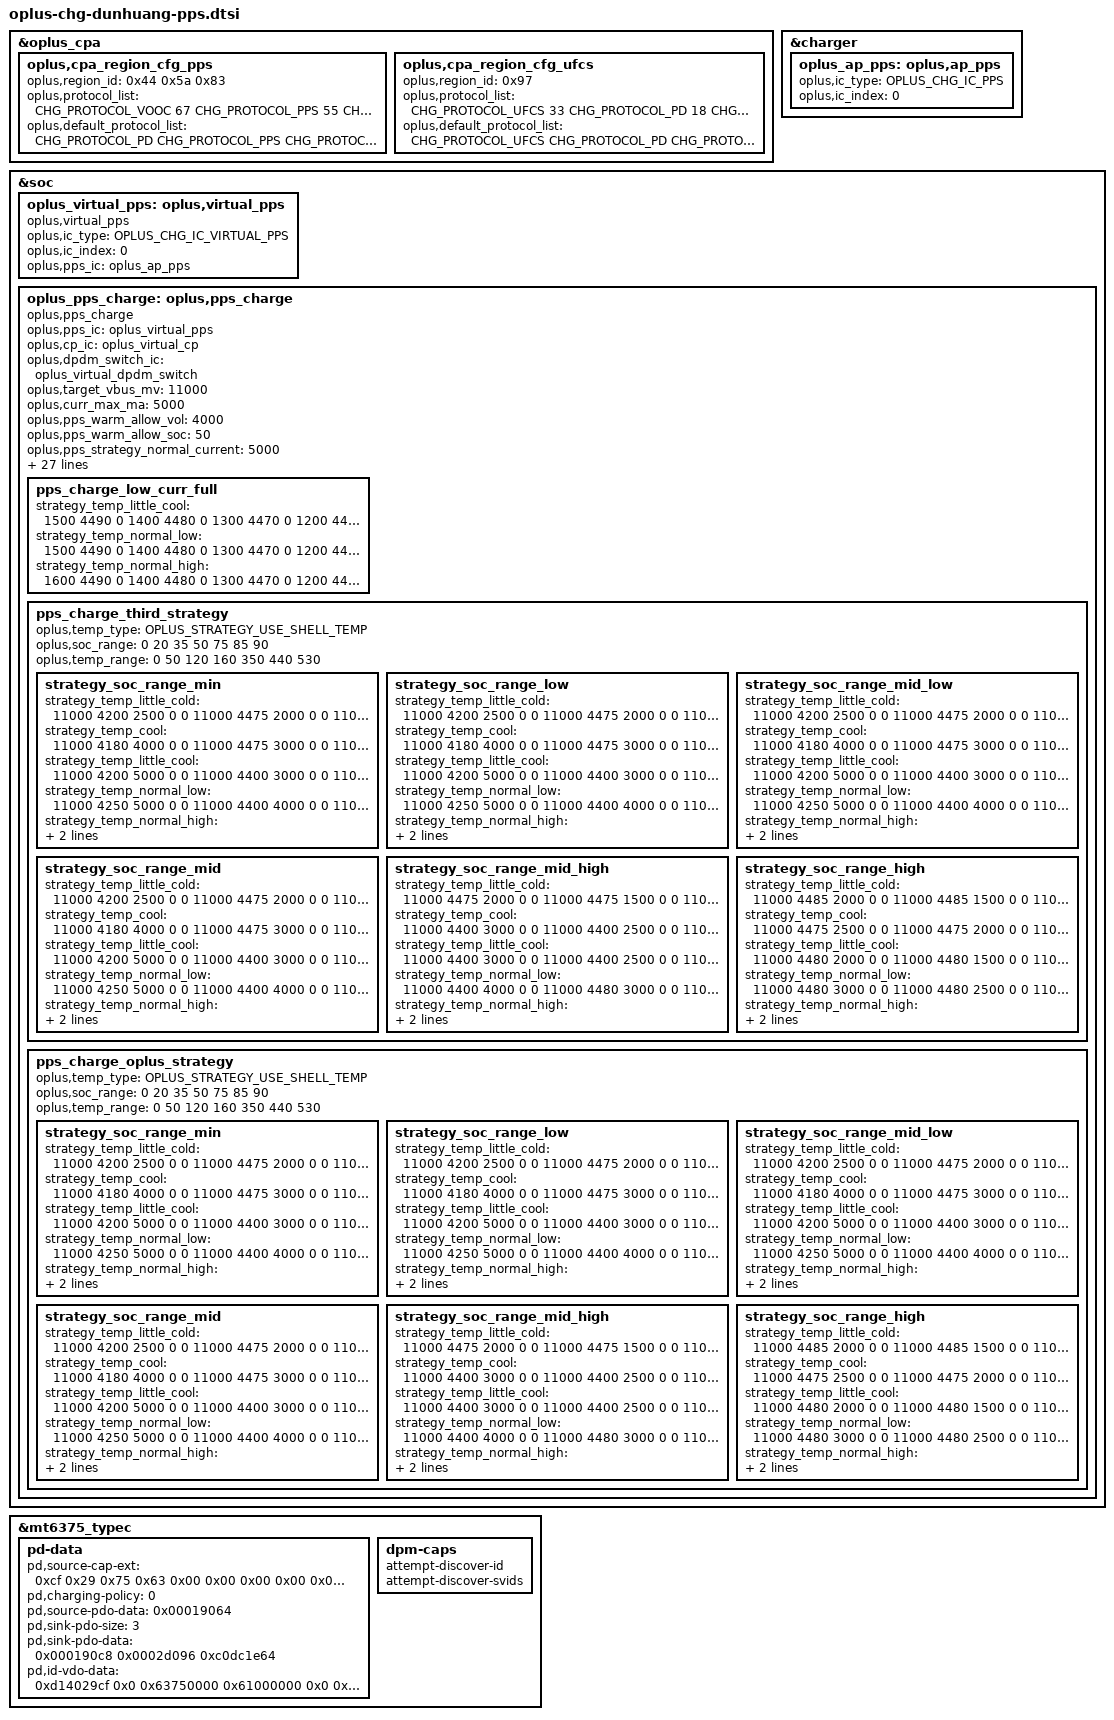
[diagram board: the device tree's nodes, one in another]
//ifdef OPLUS_FEATURE_CHG_BASIC
&oplus_cpa {
	oplus,cpa_region_cfg_pps {
		oplus,region_id = /bits/ 8 <0x44 0x5a 0x83>; /* europe: 0x44, Republic of Serbia:0x5a, Saudi Arabia: 0x83 */
		oplus,protocol_list = <CHG_PROTOCOL_VOOC 67
					CHG_PROTOCOL_PPS  55
					CHG_PROTOCOL_PD   18
					CHG_PROTOCOL_QC   18>;
		oplus,default_protocol_list = <CHG_PROTOCOL_PD
					CHG_PROTOCOL_PPS
					CHG_PROTOCOL_VOOC>;
	};
	oplus,cpa_region_cfg_ufcs {
		oplus,region_id = /bits/ 8 <0x97>; /*China:0x97*/
		oplus,protocol_list = <CHG_PROTOCOL_UFCS 33
				       CHG_PROTOCOL_PD 18
				       CHG_PROTOCOL_VOOC 67
				       CHG_PROTOCOL_QC 18>;
		oplus,default_protocol_list = <CHG_PROTOCOL_UFCS
					       CHG_PROTOCOL_PD
					       CHG_PROTOCOL_VOOC>;
	};
};

&charger {
	oplus_ap_pps: oplus,ap_pps {
		oplus,ic_type = <OPLUS_CHG_IC_PPS>;
		oplus,ic_index = <0>;
	};
};

&soc {
	oplus_virtual_pps: oplus,virtual_pps {
		compatible = "oplus,virtual_pps";

		oplus,ic_type = <OPLUS_CHG_IC_VIRTUAL_PPS>;
		oplus,ic_index = <0>;
		oplus,pps_ic = <&oplus_ap_pps>;
	};
	oplus_pps_charge: oplus,pps_charge {
		compatible = "oplus,pps_charge";
		oplus,pps_ic = <&oplus_virtual_pps>;
		oplus,cp_ic = <&oplus_virtual_cp>;
		oplus,dpdm_switch_ic = <&oplus_virtual_dpdm_switch>;

		// oplus,impedance_unit = <&oplus_pps_impedance_unit>;

		oplus,target_vbus_mv = <11000>;
		oplus,curr_max_ma = <5000>;

		oplus,pps_warm_allow_vol = <4000>;
		oplus,pps_warm_allow_soc = <50>;
		oplus,pps_strategy_normal_current = <5000>;
		oplus,pps_over_high_or_low_current = <5000>;
		oplus,pps_timeout_third = <10800>;
		oplus,pps_timeout_oplus = <10800>;
		oplus,pps_ibat_over_third = <12000>;
		oplus,pps_ibat_over_oplus = <12000>;
		oplus,pps_full_cool_sw_vbat = <4485>;
		oplus,pps_full_normal_sw_vbat = <4490>;
		oplus,pps_full_normal_hw_vbat = <4500>;
		oplus,pps_full_ffc_vbat = <4520>;
		oplus,pps_full_warm_vbat = <4130>;
		oplus,pps_full_cool_sw_vbat_third = <4485>;
		oplus,pps_full_normal_sw_vbat_third= <4490>;
		oplus,pps_full_normal_hw_vbat_third = <4500>;
		oplus,pps_current_change_timeout = <100>;
		oplus,pps_r_default = <270 45 10 45 20 20 20>;
		oplus,pps_rmos_mohm = <5>;
		oplus,pps_r_limit = <150 100 80 70 30>;
		oplus,pps_strategy_batt_high_temp = <410 420 430 400 410 420>;
		oplus,pps_strategy_high_current = <3000 2000 2000 3000 3000 3000>;
		oplus,pps_charge_strategy_soc = <0 20 35 50 75 85 90>;
		oplus,pps_charge_strategy_temp = <0 50 120 160 350 440 530>;
		oplus,pps_low_curr_full_strategy_temp = <0 200 350 440>;

		pps_charge_low_curr_full {
			strategy_temp_little_cool = 	<1500 4490 0
							 1400 4480 0
							 1300 4470 0
							 1200 4460 0
							 1100 4450 1>;
			strategy_temp_normal_low =	<1500 4490 0
                                                         1400 4480 0
                                                         1300 4470 0
                                                         1200 4460 0
                                                         1100 4450 1>;
			strategy_temp_normal_high = 	<1600 4490 0
                                                         1400 4480 0
                                                         1300 4470 0
                                                         1200 4460 0
                                                         1100 4450 1>;
		};

		pps_charge_third_strategy {
			oplus,temp_type = <OPLUS_STRATEGY_USE_SHELL_TEMP>;
			oplus,soc_range = <0 20 35 50 75 85 90>;
			oplus,temp_range = <0 50 120 160 350 440 530>;

			strategy_soc_range_min {
				strategy_temp_little_cold =	<11000 4200 2500 0 0
								11000 4475 2000 0 0
								11000 4475 1500 0 0
								11000 4485 1000 1 0>;
				strategy_temp_cool =		<11000 4180 4000 0 0
								11000 4475 3000 0 0
								11000 4475 2500 0 0
								11000 4475 2000 0 0
								11000 4475 1500 0 0
								11000 4485 1000 1 0>;
				strategy_temp_little_cool =	<11000 4200 5000 0 0
								11000 4400 3000 0 0
								11000 4400 2500 0 0
								11000 4480 2000 0 0
								11000 4480 1500 0 0
								11000 4490 1000 1 0>;
				strategy_temp_normal_low =	<11000 4250 5000 0 0
								11000 4400 4000 0 0
								11000 4480 3000 0 0
								11000 4480 2500 0 0
								11000 4480 2000 0 0
								11000 4480 1500 0 0
								11000 4490 1000 1 0>;
				strategy_temp_normal_high =	<11000 4250 5000 0 0
								11000 4400 4000 0 0
								11000 4480 3000 0 0
								11000 4480 2500 0 0
								11000 4480 2000 0 0
								11000 4480 1500 0 0
								11000 4490 1000 1 0>;
				strategy_temp_warm =		<11000 4130 1000 1 0>;
			};
			strategy_soc_range_low {
				strategy_temp_little_cold =	<11000 4200 2500 0 0
								11000 4475 2000 0 0
								11000 4475 1500 0 0
								11000 4485 1000 1 0>;
				strategy_temp_cool =		<11000 4180 4000 0 0
								11000 4475 3000 0 0
								11000 4475 2500 0 0
								11000 4475 2000 0 0
								11000 4475 1500 0 0
								11000 4485 1000 1 0>;
				strategy_temp_little_cool =	<11000 4200 5000 0 0
								11000 4400 3000 0 0
								11000 4400 2500 0 0
								11000 4480 2000 0 0
								11000 4480 1500 0 0
								11000 4490 1000 1 0>;
				strategy_temp_normal_low =	<11000 4250 5000 0 0
								11000 4400 4000 0 0
								11000 4480 3000 0 0
								11000 4480 2500 0 0
								11000 4480 2000 0 0
								11000 4480 1500 0 0
								11000 4490 1000 1 0>;
				strategy_temp_normal_high =	<11000 4250 5000 0 0
								11000 4400 4000 0 0
								11000 4480 3000 0 0
								11000 4480 2500 0 0
								11000 4480 2000 0 0
								11000 4480 1500 0 0
								11000 4490 1000 1 0>;
				strategy_temp_warm =		<11000 4130 1000 1 0>;
			};
			strategy_soc_range_mid_low {
				strategy_temp_little_cold =	<11000 4200 2500 0 0
								11000 4475 2000 0 0
								11000 4475 1500 0 0
								11000 4485 1000 1 0>;
				strategy_temp_cool =		<11000 4180 4000 0 0
								11000 4475 3000 0 0
								11000 4475 2500 0 0
								11000 4475 2000 0 0
								11000 4475 1500 0 0
								11000 4485 1000 1 0>;
				strategy_temp_little_cool =	<11000 4200 5000 0 0
								11000 4400 3000 0 0
								11000 4400 2500 0 0
								11000 4480 2000 0 0
								11000 4480 1500 0 0
								11000 4490 1000 1 0>;
				strategy_temp_normal_low =	<11000 4250 5000 0 0
								11000 4400 4000 0 0
								11000 4480 3000 0 0
								11000 4480 2500 0 0
								11000 4480 2000 0 0
								11000 4480 1500 0 0
								11000 4490 1000 1 0>;
				strategy_temp_normal_high =	<11000 4250 5000 0 0
								11000 4400 4000 0 0
								11000 4480 3000 0 0
								11000 4480 2500 0 0
								11000 4480 2000 0 0
								11000 4480 1500 0 0
								11000 4490 1000 1 0>;
				strategy_temp_warm =		<11000 4130 1000 1 0>;
			};
			strategy_soc_range_mid {
				strategy_temp_little_cold =	<11000 4200 2500 0 0
								11000 4475 2000 0 0
								11000 4475 1500 0 0
								11000 4485 1000 1 0>;
				strategy_temp_cool =		<11000 4180 4000 0 0
								11000 4475 3000 0 0
								11000 4475 2500 0 0
								11000 4475 2000 0 0
								11000 4475 1500 0 0
								11000 4485 1000 1 0>;
				strategy_temp_little_cool =	<11000 4200 5000 0 0
								11000 4400 3000 0 0
								11000 4400 2500 0 0
								11000 4480 2000 0 0
								11000 4480 1500 0 0
								11000 4490 1000 1 0>;
				strategy_temp_normal_low =	<11000 4250 5000 0 0
								11000 4400 4000 0 0
								11000 4480 3000 0 0
								11000 4480 2500 0 0
								11000 4480 2000 0 0
								11000 4480 1500 0 0
								11000 4490 1000 1 0>;
				strategy_temp_normal_high =	<11000 4250 5000 0 0
								11000 4400 4000 0 0
								11000 4480 3000 0 0
								11000 4480 2500 0 0
								11000 4480 2000 0 0
								11000 4480 1500 0 0
								11000 4490 1000 1 0>;
				strategy_temp_warm =		<11000 4130 1000 1 0>;
			};
			strategy_soc_range_mid_high {
				strategy_temp_little_cold =	<11000 4475 2000 0 0
								11000 4475 1500 0 0
								11000 4485 1000 1 0>;
				strategy_temp_cool =		<11000 4400 3000 0 0
								11000 4400 2500 0 0
								11000 4475 2000 0 0
								11000 4475 1500 0 0
								11000 4485 1000 1 0>;
				strategy_temp_little_cool =	<11000 4400 3000 0 0
								11000 4400 2500 0 0
								11000 4480 2000 0 0
								11000 4480 1500 0 0
								11000 4490 1000 1 0>;
				strategy_temp_normal_low =	<11000 4400 4000 0 0
								11000 4480 3000 0 0
								11000 4480 2500 0 0
								11000 4480 2000 0 0
								11000 4480 1500 0 0
								11000 4490 1000 1 0>;
				strategy_temp_normal_high =	<11000 4400 4000 0 0
								11000 4480 3000 0 0
								11000 4480 2500 0 0
								11000 4480 2000 0 0
								11000 4480 1500 0 0
								11000 4490 1000 1 0>;
				strategy_temp_warm =		<11000 4130 1000 1 0>;
			};
			strategy_soc_range_high {
				strategy_temp_little_cold =	<11000 4485 2000 0 0
								11000 4485 1500 0 0
								11000 4485 1000 1 0>;
				strategy_temp_cool =		<11000 4475 2500 0 0
								11000 4475 2000 0 0
								11000 4475 1500 0 0
								11000 4485 1000 1 0>;
				strategy_temp_little_cool =	<11000 4480 2000 0 0
								11000 4480 1500 0 0
								11000 4490 1000 1 0>;
				strategy_temp_normal_low =	<11000 4480 3000 0 0
								11000 4480 2500 0 0
								11000 4480 2000 0 0
								11000 4480 1500 0 0
								11000 4490 1000 1 0>;
				strategy_temp_normal_high =	<11000 4480 3000 0 0
								11000 4480 2500 0 0
								11000 4480 2000 0 0
								11000 4480 1500 0 0
								11000 4490 1000 1 0>;
				strategy_temp_warm =		<11000 4130 1000 1 0>;
			};
		};

		pps_charge_oplus_strategy {
			oplus,temp_type = <OPLUS_STRATEGY_USE_SHELL_TEMP>;
			oplus,soc_range = <0 20 35 50 75 85 90>;
			oplus,temp_range = <0 50 120 160 350 440 530>;

			strategy_soc_range_min {
				strategy_temp_little_cold =	<11000 4200 2500 0 0
								11000 4475 2000 0 0
								11000 4475 1500 0 0
								11000 4485 1000 1 0>;
				strategy_temp_cool =		<11000 4180 4000 0 0
								11000 4475 3000 0 0
								11000 4475 2500 0 0
								11000 4475 2000 0 0
								11000 4475 1500 0 0
								11000 4485 1000 1 0>;
				strategy_temp_little_cool =	<11000 4200 5000 0 0
								11000 4400 3000 0 0
								11000 4400 2500 0 0
								11000 4480 2000 0 0
								11000 4480 1500 0 0
								11000 4490 1000 1 0>;
				strategy_temp_normal_low =	<11000 4250 5000 0 0
								11000 4400 4000 0 0
								11000 4480 3000 0 0
								11000 4480 2500 0 0
								11000 4480 2000 0 0
								11000 4480 1500 0 0
								11000 4490 1000 1 0>;
				strategy_temp_normal_high =	<11000 4250 5000 0 0
								11000 4400 4000 0 0
								11000 4480 3000 0 0
								11000 4480 2500 0 0
								11000 4480 2000 0 0
								11000 4480 1500 0 0
								11000 4490 1000 1 0>;
				strategy_temp_warm =		<11000 4130 1000 1 0>;
			};
			strategy_soc_range_low {
				strategy_temp_little_cold =	<11000 4200 2500 0 0
								11000 4475 2000 0 0
								11000 4475 1500 0 0
								11000 4485 1000 1 0>;
				strategy_temp_cool =		<11000 4180 4000 0 0
								11000 4475 3000 0 0
								11000 4475 2500 0 0
								11000 4475 2000 0 0
								11000 4475 1500 0 0
								11000 4485 1000 1 0>;
				strategy_temp_little_cool =	<11000 4200 5000 0 0
								11000 4400 3000 0 0
								11000 4400 2500 0 0
								11000 4480 2000 0 0
								11000 4480 1500 0 0
								11000 4490 1000 1 0>;
				strategy_temp_normal_low =	<11000 4250 5000 0 0
								11000 4400 4000 0 0
								11000 4480 3000 0 0
								11000 4480 2500 0 0
								11000 4480 2000 0 0
								11000 4480 1500 0 0
								11000 4490 1000 1 0>;
				strategy_temp_normal_high =	<11000 4250 5000 0 0
								11000 4400 4000 0 0
								11000 4480 3000 0 0
								11000 4480 2500 0 0
								11000 4480 2000 0 0
								11000 4480 1500 0 0
								11000 4490 1000 1 0>;
				strategy_temp_warm =		<11000 4130 1000 1 0>;
			};
			strategy_soc_range_mid_low {
				strategy_temp_little_cold =	<11000 4200 2500 0 0
								11000 4475 2000 0 0
								11000 4475 1500 0 0
								11000 4485 1000 1 0>;
				strategy_temp_cool =		<11000 4180 4000 0 0
								11000 4475 3000 0 0
								11000 4475 2500 0 0
								11000 4475 2000 0 0
								11000 4475 1500 0 0
								11000 4485 1000 1 0>;
				strategy_temp_little_cool =	<11000 4200 5000 0 0
								11000 4400 3000 0 0
								11000 4400 2500 0 0
								11000 4480 2000 0 0
								11000 4480 1500 0 0
								11000 4490 1000 1 0>;
				strategy_temp_normal_low =	<11000 4250 5000 0 0
								11000 4400 4000 0 0
								11000 4480 3000 0 0
								11000 4480 2500 0 0
								11000 4480 2000 0 0
								11000 4480 1500 0 0
								11000 4490 1000 1 0>;
				strategy_temp_normal_high =	<11000 4250 5000 0 0
								11000 4400 4000 0 0
								11000 4480 3000 0 0
								11000 4480 2500 0 0
								11000 4480 2000 0 0
								11000 4480 1500 0 0
								11000 4490 1000 1 0>;
				strategy_temp_warm =		<11000 4130 1000 1 0>;
			};
			strategy_soc_range_mid {
				strategy_temp_little_cold =	<11000 4200 2500 0 0
								11000 4475 2000 0 0
								11000 4475 1500 0 0
								11000 4485 1000 1 0>;
				strategy_temp_cool =		<11000 4180 4000 0 0
								11000 4475 3000 0 0
								11000 4475 2500 0 0
								11000 4475 2000 0 0
								11000 4475 1500 0 0
								11000 4485 1000 1 0>;
				strategy_temp_little_cool =	<11000 4200 5000 0 0
								11000 4400 3000 0 0
								11000 4400 2500 0 0
								11000 4480 2000 0 0
								11000 4480 1500 0 0
								11000 4490 1000 1 0>;
				strategy_temp_normal_low =	<11000 4250 5000 0 0
								11000 4400 4000 0 0
								11000 4480 3000 0 0
								11000 4480 2500 0 0
								11000 4480 2000 0 0
								11000 4480 1500 0 0
								11000 4490 1000 1 0>;
				strategy_temp_normal_high =	<11000 4250 5000 0 0
								11000 4400 4000 0 0
								11000 4480 3000 0 0
								11000 4480 2500 0 0
								11000 4480 2000 0 0
								11000 4480 1500 0 0
								11000 4490 1000 1 0>;
				strategy_temp_warm =		<11000 4130 1000 1 0>;
			};
			strategy_soc_range_mid_high {
				strategy_temp_little_cold =	<11000 4475 2000 0 0
								11000 4475 1500 0 0
								11000 4485 1000 1 0>;
				strategy_temp_cool =		<11000 4400 3000 0 0
								11000 4400 2500 0 0
								11000 4475 2000 0 0
								11000 4475 1500 0 0
								11000 4485 1000 1 0>;
				strategy_temp_little_cool =	<11000 4400 3000 0 0
								11000 4400 2500 0 0
								11000 4480 2000 0 0
								11000 4480 1500 0 0
								11000 4490 1000 1 0>;
				strategy_temp_normal_low =	<11000 4400 4000 0 0
								11000 4480 3000 0 0
								11000 4480 2500 0 0
								11000 4480 2000 0 0
								11000 4480 1500 0 0
								11000 4490 1000 1 0>;
				strategy_temp_normal_high =	<11000 4400 4000 0 0
								11000 4480 3000 0 0
								11000 4480 2500 0 0
								11000 4480 2000 0 0
								11000 4480 1500 0 0
								11000 4490 1000 1 0>;
				strategy_temp_warm =		<11000 4130 1000 1 0>;
			};
			strategy_soc_range_high {
				strategy_temp_little_cold =	<11000 4485 2000 0 0
								11000 4485 1500 0 0
								11000 4485 1000 1 0>;
				strategy_temp_cool =		<11000 4475 2500 0 0
								11000 4475 2000 0 0
								11000 4475 1500 0 0
								11000 4485 1000 1 0>;
				strategy_temp_little_cool =	<11000 4480 2000 0 0
								11000 4480 1500 0 0
								11000 4490 1000 1 0>;
				strategy_temp_normal_low =	<11000 4480 3000 0 0
								11000 4480 2500 0 0
								11000 4480 2000 0 0
								11000 4480 1500 0 0
								11000 4490 1000 1 0>;
				strategy_temp_normal_high =	<11000 4480 3000 0 0
								11000 4480 2500 0 0
								11000 4480 2000 0 0
								11000 4480 1500 0 0
								11000 4490 1000 1 0>;
				strategy_temp_warm =		<11000 4130 1000 1 0>;
			};
		};
	};
};

/* for pd common charger */
&mt6375_typec {
	pd-data {
			pd,source-cap-ext = /bits/ 8 <0xcf 0x29 0x75 0x63
							      0x00 0x00 0x00 0x00
							      0x00 0x00 0x00 0x00
							      0x00 0x00 0x00 0x00
							      0x00 0x00 0x00 0x00
							      0x00 0x00 0x01 0x05
							      0x00>;

			pd,charging-policy = <0>;

			pd,source-pdo-data = <0x00019064>;/* Fixed, 5000mV, 1000mA*/

			/*0x000190c8: Fixed, 5000mV, 2000mA*/
			/*0x0002d096: Fixed, 9000mV, 1500mA*/
			/*0xc0dc1e64: apdo, min 3000mV, max 11000mV, 5000mA*/
			pd,sink-pdo-size = <3>;
			pd,sink-pdo-data = <0x000190c8 0x0002d096 0xc0dc1e64>;

			/* No DP, host + device */
			pd,id-vdo-data = <0xd14029cf 0x0 0x63750000
						  0x61000000 0x0 0x41000000>;
	};

	dpm-caps {
			// attempt-enter-dp-mode;
			attempt-discover-id;
			attempt-discover-svids;
	};
};

//#endif OPLUS_FEATURE_CHG_BASIC
